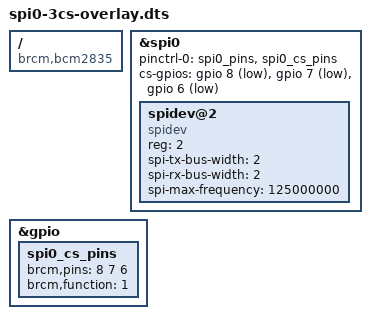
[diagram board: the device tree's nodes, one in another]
/dts-v1/;
/plugin/;

/ {
	compatible = "brcm,bcm2835", "brcm,bcm2836", "brcm,bcm2708", "brcm,bcm2709";

	fragment@0 {
		target = <&spi0>;
		frag0: __overlay__ {
			#address-cells = <1>;
			#size-cells = <0>;
			pinctrl-0 = <&spi0_pins &spi0_cs_pins>;
			status = "okay";
			cs-gpios = <&gpio 8 1>, <&gpio 7 1>, <&gpio 6 1>;

			spidev@2{
				compatible = "spidev";
				reg = <2>;	/* CE2 */
				#address-cells = <1>;
				#size-cells = <0>;
				spi-tx-bus-width = <2>;
				spi-rx-bus-width = <2>;
				spi-max-frequency = <125000000>;
			};
		};
	};

	fragment@1 {
		target = <&gpio>;
		__overlay__ {
			spi0_cs_pins: spi0_cs_pins {
				brcm,pins = <8 7 6>;
				brcm,function = <1>; /* out */
			};
		};
	};

	__overrides__ {
		cs2_pin = <&frag0>,"cs-gpios:12", <&spi0_cs_pins>,"brcm,pins:0";
	};
};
